AUTOSAR XML (schema 4-2-2)
package /SensorActuator_DIO
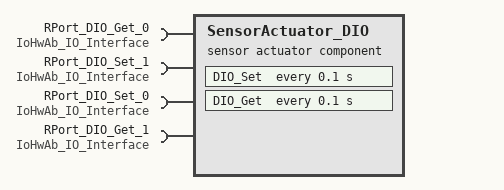
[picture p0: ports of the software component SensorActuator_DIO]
  sensor actuator sw component type SensorActuator_DIO
    4 x require port, all with required-interface=IoHwAb_IO_Interface:
      RPort_DIO_Get_0
      RPort_DIO_Set_1
      RPort_DIO_Set_0
      RPort_DIO_Get_1
    behavior IB_SensorActuator_DIO
      timing event TimingEvent_0: start-on-event=DIO_Set, period=0.1
      timing event TimingEvent_1: start-on-event=DIO_Get, period=0.1
      runnable DIO_Set: symbol=DIO_Set_func
        sync call SynchronousServerCallPoint_0: operation=RPort_DIO_Set_1.IoHwAb_IO_Set
        sync call SynchronousServerCallPoint_2: operation=RPort_DIO_Set_0.IoHwAb_IO_Set
      runnable DIO_Get: symbol=DIO_Get_func
        sync call SynchronousServerCallPoint_0: operation=RPort_DIO_Get_0.IoHwAb_IO_Get
        sync call SynchronousServerCallPoint_2: operation=RPort_DIO_Get_1.IoHwAb_IO_Get
